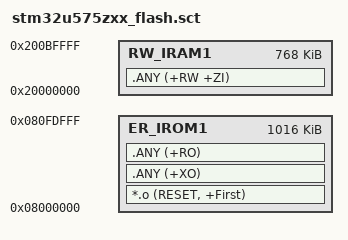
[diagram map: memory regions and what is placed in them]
; *********************************************************************************
; *** Scatter-Loading Description File generated by STM32CubeMX/LinkerGenerator ***
; *********************************************************************************;

LR_IROM1 0x08000000 0x000fe000  {  ; load_region size_region
  ER_IROM1 0x08000000 0x000fe000  {  ; load address = excetion address
   *.o (RESET, +First)
   .ANY (+XO)
   .ANY (+RO)
  }
  RW_IRAM1 0x20000000 0x000c0000  {  ; load address = excetion address
   .ANY (+RW +ZI)
  }
}

